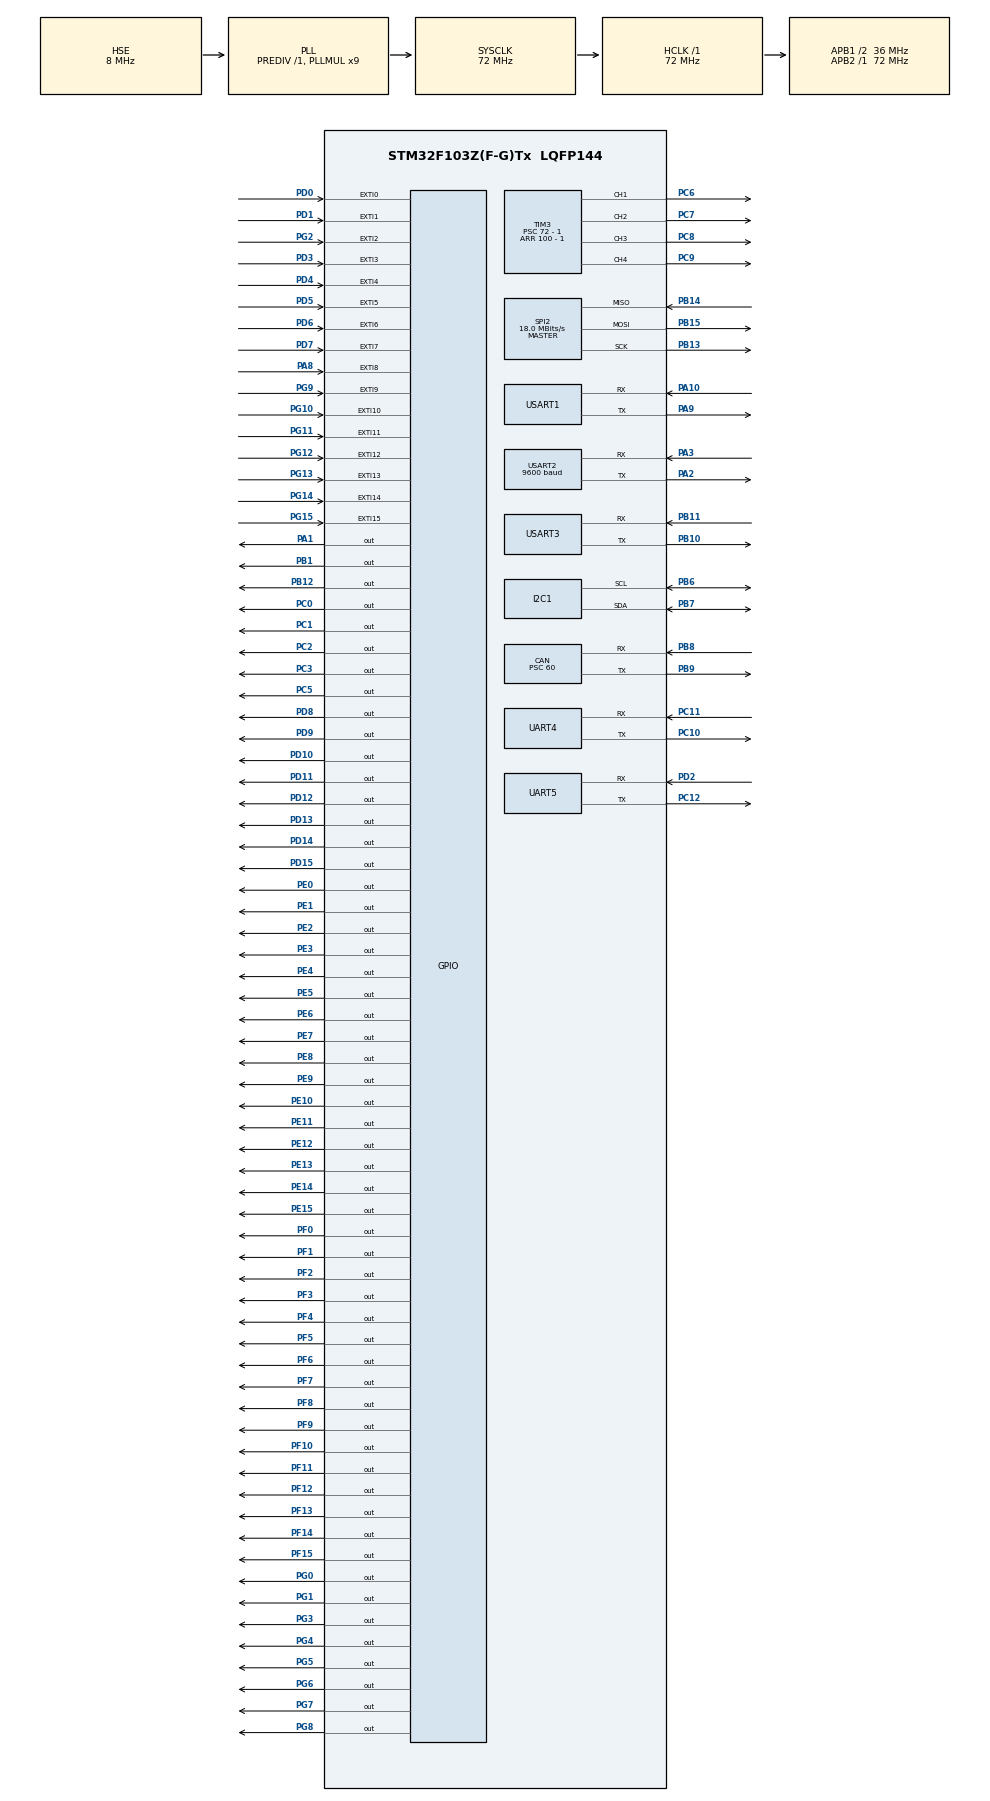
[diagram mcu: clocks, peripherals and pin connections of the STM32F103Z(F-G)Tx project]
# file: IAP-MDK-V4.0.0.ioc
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CAN.BS1=CAN_BS1_3TQ
CAN.BS2=CAN_BS2_2TQ
CAN.CalculateTimeBit=10000
CAN.CalculateTimeQuantum=1666.6666666666667
CAN.Prescaler=60
I2C1.AddressingMode=I2C_ADDRESSINGMODE_7BIT
I2C1.OwnAddress=0x0A
Mcu.Family=STM32F1
Mcu.Name=STM32F103Z(F-G)Tx
Mcu.Package=LQFP144
NVIC.EXTI0_IRQn=true\:0\:1\:true\:false\:true\:true
NVIC.EXTI15_10_IRQn=true\:0\:1\:false\:false\:true\:true
NVIC.EXTI1_IRQn=true\:0\:1\:true\:false\:true\:true
NVIC.EXTI2_IRQn=true\:0\:1\:false\:false\:true\:true
NVIC.EXTI3_IRQn=true\:0\:1\:false\:false\:true\:true
NVIC.EXTI4_IRQn=true\:0\:1\:false\:false\:true\:true
NVIC.EXTI9_5_IRQn=true\:0\:1\:false\:false\:true\:true
NVIC.I2C1_EV_IRQn=true\:0\:0\:false\:false\:true\:true
NVIC.PriorityGroup=NVIC_PRIORITYGROUP_2
NVIC.TIM1_BRK_TIM9_IRQn=true\:2\:0\:true\:false\:true\:true
NVIC.TIM1_TRG_COM_TIM11_IRQn=true\:2\:0\:true\:false\:true\:true
NVIC.TIM1_UP_TIM10_IRQn=true\:2\:0\:true\:false\:true\:true
NVIC.TIM5_IRQn=true\:2\:0\:true\:false\:true\:true
NVIC.TIM6_IRQn=true\:2\:0\:true\:false\:true\:true
NVIC.TIM7_IRQn=true\:2\:0\:true\:false\:true\:true
NVIC.TIM8_BRK_TIM12_IRQn=true\:2\:0\:true\:false\:true\:true
NVIC.TIM8_TRG_COM_TIM14_IRQn=true\:2\:0\:true\:false\:true\:true
NVIC.TIM8_UP_TIM13_IRQn=true\:2\:0\:true\:false\:true\:true
NVIC.UART4_IRQn=true\:1\:2\:true\:false\:true\:true
NVIC.UART5_IRQn=true\:1\:2\:true\:false\:true\:true
NVIC.USART1_IRQn=true\:1\:1\:true\:false\:true\:true
NVIC.USART2_IRQn=true\:1\:1\:true\:false\:true\:true
NVIC.USART3_IRQn=true\:1\:0\:true\:false\:true\:true
NVIC.USB_HP_CAN1_TX_IRQn=true\:0\:0\:false\:false\:true\:true
NVIC.USB_LP_CAN1_RX0_IRQn=true\:0\:0\:false\:false\:true\:false
OSC_IN.Mode=HSE-External-Oscillator
OSC_IN.Signal=RCC_OSC_IN
OSC_OUT.Mode=HSE-External-Oscillator
OSC_OUT.Signal=RCC_OSC_OUT
PA1.Signal=GPIO_Output
PA10.Mode=Asynchronous
PA10.Signal=USART1_RX
PA13.Mode=JTAG_5_pins
PA13.Signal=SYS_JTMS-SWDIO
PA14.Mode=JTAG_5_pins
PA14.Signal=SYS_JTCK-SWCLK
PA15.Mode=JTAG_5_pins
PA15.Signal=SYS_JTDI
PA2.Mode=Asynchronous
PA2.Signal=USART2_TX
PA3.Mode=Asynchronous
PA3.Signal=USART2_RX
PA8.GPIO_ModeDefaultEXTI=GPIO_MODE_IT_RISING_FALLING
PA8.Signal=GPXTI8
PA9.Mode=Asynchronous
PA9.Signal=USART1_TX
PB1.Signal=GPIO_Output
PB10.Mode=Asynchronous
PB10.Signal=USART3_TX
PB11.Mode=Asynchronous
PB11.Signal=USART3_RX
PB12.Signal=GPIO_Output
PB13.Mode=Full_Duplex_Master
PB13.Signal=SPI2_SCK
PB14.Mode=Full_Duplex_Master
PB14.Signal=SPI2_MISO
PB15.Mode=Full_Duplex_Master
PB15.Signal=SPI2_MOSI
PB3.Mode=JTAG_5_pins
PB3.Signal=SYS_JTDO-TRACESWO
PB4.Mode=JTAG_5_pins
PB4.Signal=SYS_NJTRST
PB6.Mode=I2C
PB6.Signal=I2C1_SCL
PB7.Mode=I2C
PB7.Signal=I2C1_SDA
PB8.Mode=Master
PB8.Signal=CAN_RX
PB9.Mode=Master
PB9.Signal=CAN_TX
PC0.Signal=GPIO_Output
PC1.Signal=GPIO_Output
PC10.Mode=Asynchronous
PC10.Signal=UART4_TX
PC11.Mode=Asynchronous
PC11.Signal=UART4_RX
PC12.Mode=Asynchronous
PC12.Signal=UART5_TX
PC14-OSC32_IN.Mode=LSE-External-Oscillator
PC14-OSC32_IN.Signal=RCC_OSC32_IN
PC15-OSC32_OUT.Mode=LSE-External-Oscillator
PC15-OSC32_OUT.Signal=RCC_OSC32_OUT
PC2.Signal=GPIO_Output
PC3.Signal=GPIO_Output
PC5.Signal=GPIO_Output
PC6.Signal=S_TIM3_CH1
PC7.Signal=S_TIM3_CH2
PC8.Signal=S_TIM3_CH3
PC9.Signal=S_TIM3_CH4
PD0.GPIO_ModeDefaultEXTI=GPIO_MODE_IT_RISING_FALLING
PD0.Signal=GPXTI0
PD1.GPIO_ModeDefaultEXTI=GPIO_MODE_IT_RISING_FALLING
PD1.Signal=GPXTI1
PD10.Signal=GPIO_Output
PD11.Signal=GPIO_Output
PD12.Signal=GPIO_Output
PD13.Signal=GPIO_Output
PD14.Signal=GPIO_Output
PD15.Signal=GPIO_Output
PD2.Mode=Asynchronous
PD2.Signal=UART5_RX
PD3.GPIO_ModeDefaultEXTI=GPIO_MODE_IT_RISING_FALLING
PD3.Signal=GPXTI3
PD4.GPIO_ModeDefaultEXTI=GPIO_MODE_IT_RISING_FALLING
PD4.Signal=GPXTI4
PD5.GPIO_ModeDefaultEXTI=GPIO_MODE_IT_RISING_FALLING
PD5.Signal=GPXTI5
PD6.GPIO_ModeDefaultEXTI=GPIO_MODE_IT_RISING_FALLING
PD6.Signal=GPXTI6
PD7.GPIO_ModeDefaultEXTI=GPIO_MODE_IT_RISING_FALLING
PD7.Signal=GPXTI7
PD8.Signal=GPIO_Output
PD9.Signal=GPIO_Output
PE0.Signal=GPIO_Output
PE1.Signal=GPIO_Output
PE10.Signal=GPIO_Output
PE11.Signal=GPIO_Output
PE12.Signal=GPIO_Output
PE13.Signal=GPIO_Output
PE14.Signal=GPIO_Output
PE15.Signal=GPIO_Output
PE2.Signal=GPIO_Output
PE3.Signal=GPIO_Output
PE4.Signal=GPIO_Output
PE5.Signal=GPIO_Output
PE6.Signal=GPIO_Output
PE7.Signal=GPIO_Output
PE8.Signal=GPIO_Output
PE9.Signal=GPIO_Output
PF0.Signal=GPIO_Output
PF1.Signal=GPIO_Output
PF10.Signal=GPIO_Output
PF11.Signal=GPIO_Output
PF12.Signal=GPIO_Output
PF13.Signal=GPIO_Output
PF14.Signal=GPIO_Output
PF15.Signal=GPIO_Output
PF2.Signal=GPIO_Output
PF3.Signal=GPIO_Output
PF4.Signal=GPIO_Output
PF5.Signal=GPIO_Output
PF6.Signal=GPIO_Output
PF7.Signal=GPIO_Output
PF8.Signal=GPIO_Output
PF9.Signal=GPIO_Output
PG0.Signal=GPIO_Output
PG1.Signal=GPIO_Output
PG10.GPIO_ModeDefaultEXTI=GPIO_MODE_IT_RISING_FALLING
PG10.Signal=GPXTI10
PG11.GPIO_ModeDefaultEXTI=GPIO_MODE_IT_RISING_FALLING
PG11.Signal=GPXTI11
PG12.GPIO_ModeDefaultEXTI=GPIO_MODE_IT_RISING_FALLING
PG12.Signal=GPXTI12
PG13.GPIO_ModeDefaultEXTI=GPIO_MODE_IT_RISING_FALLING
PG13.Signal=GPXTI13
PG14.GPIO_ModeDefaultEXTI=GPIO_MODE_IT_RISING_FALLING
PG14.Signal=GPXTI14
PG15.GPIO_ModeDefaultEXTI=GPIO_MODE_IT_RISING_FALLING
PG15.Signal=GPXTI15
PG2.GPIO_ModeDefaultEXTI=GPIO_MODE_IT_RISING_FALLING
PG2.Signal=GPXTI2
PG3.Signal=GPIO_Output
PG4.Signal=GPIO_Output
PG5.Signal=GPIO_Output
PG6.Signal=GPIO_Output
PG7.Signal=GPIO_Output
PG8.Signal=GPIO_Output
PG9.GPIO_ModeDefaultEXTI=GPIO_MODE_IT_RISING_FALLING
PG9.Signal=GPXTI9
ProjectManager.HeapSize=0x4000
ProjectManager.StackSize=0x5000
ProjectManager.TargetToolchain=MDK-ARM V5
RCC.AHBFreq_Value=72000000
RCC.APB1CLKDivider=RCC_HCLK_DIV2
RCC.APB1Freq_Value=36000000
RCC.APB1TimFreq_Value=72000000
RCC.APB2Freq_Value=72000000
RCC.APB2TimFreq_Value=72000000
RCC.HCLKFreq_Value=72000000
RCC.PLLMUL=RCC_PLL_MUL9
RCC.PLLSourceVirtual=RCC_PLLSOURCE_HSE
RCC.SYSCLKFreq_VALUE=72000000
RCC.SYSCLKSource=RCC_SYSCLKSOURCE_PLLCLK
RCC.USBFreq_Value=48000000
RCC.USBPrescaler=RCC_USBCLKSOURCE_PLL_DIV1_5
SH.S_TIM3_CH1.0=TIM3_CH1,PWM Generation1 CH1
SH.S_TIM3_CH2.0=TIM3_CH2,PWM Generation2 CH2
SH.S_TIM3_CH3.0=TIM3_CH3,PWM Generation3 CH3
SH.S_TIM3_CH4.0=TIM3_CH4,PWM Generation4 CH4
SPI2.BaudRatePrescaler=SPI_BAUDRATEPRESCALER_2
SPI2.CRCCalculation=SPI_CRCCALCULATION_ENABLE
SPI2.CalculateBaudRate=18.0 MBits/s
SPI2.Direction=SPI_DIRECTION_2LINES
SPI2.Mode=SPI_MODE_MASTER
SPI2.VirtualType=VM_MASTER
TIM10.Period=4 - 1
TIM10.Prescaler=72 - 1
TIM11.Period=4 - 1
TIM11.Prescaler=72 - 1
TIM12.Period=4 - 1
TIM12.Prescaler=72 - 1
TIM13.Period=4 - 1
TIM13.Prescaler=72 - 1
TIM14.Period=4 - 1
TIM14.Prescaler=72 - 1
TIM3.Channel-PWM\ Generation1\ CH1=TIM_CHANNEL_1
TIM3.Channel-PWM\ Generation2\ CH2=TIM_CHANNEL_2
TIM3.Channel-PWM\ Generation3\ CH3=TIM_CHANNEL_3
TIM3.Channel-PWM\ Generation4\ CH4=TIM_CHANNEL_4
TIM3.Period=100 - 1
TIM3.Prescaler=72 - 1
TIM5.Period=4 - 1
TIM5.Prescaler=72 - 1
TIM6.Period=4 - 1
TIM6.Prescaler=72 - 1
TIM7.Period=4 - 1
TIM7.Prescaler=72 - 1
TIM8.Period=4 - 1
TIM8.Prescaler=72 - 1
TIM9.Period=4 - 1
TIM9.Prescaler=72 - 1
UART4.VirtualMode=Asynchronous
UART5.VirtualMode=Asynchronous
USART1.VirtualMode=VM_ASYNC
USART2.BaudRate=9600
USART2.VirtualMode=VM_ASYNC
USART3.VirtualMode=VM_ASYNC
VP_TIM10_VS_ClockSourceINT.Mode=Enable_Timer
VP_TIM11_VS_ClockSourceINT.Mode=Enable_Timer
VP_TIM12_VS_ClockSourceINT.Mode=Internal
VP_TIM13_VS_ClockSourceINT.Mode=Enable_Timer
VP_TIM14_VS_ClockSourceINT.Mode=Enable_Timer
VP_TIM5_VS_ClockSourceINT.Mode=Internal
VP_TIM6_VS_ClockSourceINT.Mode=Enable_Timer
VP_TIM7_VS_ClockSourceINT.Mode=Enable_Timer
VP_TIM8_VS_ClockSourceINT.Mode=Internal
VP_TIM9_VS_ClockSourceINT.Mode=Internal
board=custom

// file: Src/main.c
/* USER CODE BEGIN Header */
/**
  ******************************************************************************
  * @file           : main.c
  * @brief          : Main program body
  ******************************************************************************
  * This notice applies to any and all portions of this file
  * that are not between comment pairs USER CODE BEGIN and
  * USER CODE END. Other portions of this file, whether
  * inserted by the user or by software development tools
  * are owned by their respective copyright owners.
  *
  * Copyright (c) 2019 STMicroelectronics International N.V.
  * All rights reserved.
  *
  * Redistribution and use in source and binary forms, with or without
  * modification, are permitted, provided that the following conditions are met:
  *
  * 1. Redistribution of source code must retain the above copyright notice,
  *    this list of conditions and the following disclaimer.
  * 2. Redistributions in binary form must reproduce the above copyright notice,
  *    this list of conditions and the following disclaimer in the documentation
  *    and/or other materials provided with the distribution.
  * 3. Neither the name of STMicroelectronics nor the names of other
  *    contributors to this software may be used to endorse or promote products
  *    derived from this software without specific written permission.
  * 4. This software, including modifications and/or derivative works of this
  *    software, must execute solely and exclusively on microcontroller or
  *    microprocessor devices manufactured by or for STMicroelectronics.
  * 5. Redistribution and use of this software other than as permitted under
  *    this license is void and will automatically terminate your rights under
  *    this license.
  *
  * THIS SOFTWARE IS PROVIDED BY STMICROELECTRONICS AND CONTRIBUTORS "AS IS"
  * AND ANY EXPRESS, IMPLIED OR STATUTORY WARRANTIES, INCLUDING, BUT NOT
  * LIMITED TO, THE IMPLIED WARRANTIES OF MERCHANTABILITY, FITNESS FOR A
  * PARTICULAR PURPOSE AND NON-INFRINGEMENT OF THIRD PARTY INTELLECTUAL PROPERTY
  * RIGHTS ARE DISCLAIMED TO THE FULLEST EXTENT PERMITTED BY LAW. IN NO EVENT
  * SHALL STMICROELECTRONICS OR CONTRIBUTORS BE LIABLE FOR ANY DIRECT, INDIRECT,
  * INCIDENTAL, SPECIAL, EXEMPLARY, OR CONSEQUENTIAL DAMAGES (INCLUDING, BUT NOT
  * LIMITED TO, PROCUREMENT OF SUBSTITUTE GOODS OR SERVICES; LOSS OF USE, DATA,
  * OR PROFITS; OR BUSINESS INTERRUPTION) HOWEVER CAUSED AND ON ANY THEORY OF
  * LIABILITY, WHETHER IN CONTRACT, STRICT LIABILITY, OR TORT (INCLUDING
  * NEGLIGENCE OR OTHERWISE) ARISING IN ANY WAY OUT OF THE USE OF THIS SOFTWARE,
  * EVEN IF ADVISED OF THE POSSIBILITY OF SUCH DAMAGE.
  *
  ******************************************************************************
  */
/* USER CODE END Header */

#include "main.h"

/* USER CODE BEGIN Includes */
#include "mb_type.h"
#include "mb_user.h"

#include "plc_user.h"
#include "plc_eep.h"

/* USER CODE END Includes */

CAN_HandleTypeDef hcan;

I2C_HandleTypeDef hi2c1;

SPI_HandleTypeDef hspi2;

TIM_HandleTypeDef htim3;
TIM_HandleTypeDef htim5;
TIM_HandleTypeDef htim6;
TIM_HandleTypeDef htim7;
TIM_HandleTypeDef htim8;
TIM_HandleTypeDef htim9;
TIM_HandleTypeDef htim10;
TIM_HandleTypeDef htim11;
TIM_HandleTypeDef htim12;
TIM_HandleTypeDef htim13;
TIM_HandleTypeDef htim14;

UART_HandleTypeDef huart4;
UART_HandleTypeDef huart5;
UART_HandleTypeDef huart1;
UART_HandleTypeDef huart2;
UART_HandleTypeDef huart3;

void SystemClock_Config(void);
static void MX_GPIO_Init(void);
static void MX_USART1_UART_Init(void);
static void MX_USART2_UART_Init(void);
static void MX_USART3_UART_Init(void);
static void MX_UART4_Init(void);
static void MX_UART5_Init(void);
static void MX_I2C1_Init(void);
static void MX_SPI2_Init(void);
static void MX_TIM3_Init(void);
static void MX_TIM11_Init(void);
static void MX_TIM7_Init(void);
static void MX_TIM8_Init(void);
static void MX_TIM9_Init(void);
static void MX_TIM10_Init(void);
static void MX_TIM12_Init(void);
static void MX_TIM13_Init(void);
static void MX_TIM14_Init(void);
static void MX_TIM6_Init(void);
static void MX_TIM5_Init(void);
static void MX_CAN_Init(void);

int main(void)
{
  /* USER CODE BEGIN 1 */
	uint8_t scan_enable;
	//uint8_t ReadValue;

  /* USER CODE END 1 */

  /* MCU Configuration--------------------------------------------------------*/

  /* Reset of all peripherals, Initializes the Flash interface and the Systick. */
  HAL_Init();

  /* Configure the system clock */
  SystemClock_Config();

  /* Initialize all configured peripherals */
  MX_GPIO_Init();
  MX_USART1_UART_Init();
  MX_USART2_UART_Init();
  MX_USART3_UART_Init();
  MX_UART4_Init();
  MX_UART5_Init();
  MX_I2C1_Init();
  MX_SPI2_Init();
  MX_TIM3_Init();
  MX_TIM11_Init();
  MX_TIM7_Init();
  MX_TIM8_Init();
  MX_TIM9_Init();
  MX_TIM10_Init();
  MX_TIM12_Init();
  MX_TIM13_Init();
  MX_TIM14_Init();
  MX_TIM6_Init();
  MX_TIM5_Init();
  MX_CAN_Init();
  /* USER CODE BEGIN 2 */
	// 时钟节拍
	HAL_SetTickFreq(HAL_TICK_FREQ_1KHZ);

	// 端口初始化
	plc_user_init();

	//modbus 端口初始化
	mb_user_init();

  /* USER CODE END 2 */

  /* Infinite loop */
  /* USER CODE BEGIN WHILE */
  while (1)
  {
	  // plc扫描
		scan_enable = plc_user_scan(scan_enable);

		// modbus扫描
		if(scan_enable == FALSE){
			scan_enable = mb_user_poll();
		}

    /* USER CODE END WHILE */

  }
}

void SystemClock_Config(void)
{
  RCC_OscInitTypeDef RCC_OscInitStruct = {0};
  RCC_ClkInitTypeDef RCC_ClkInitStruct = {0};

  /**Initializes the CPU, AHB and APB busses clocks
  */
  RCC_OscInitStruct.OscillatorType = RCC_OSCILLATORTYPE_HSE;
  RCC_OscInitStruct.HSEState = RCC_HSE_ON;
  RCC_OscInitStruct.HSEPredivValue = RCC_HSE_PREDIV_DIV1;
  RCC_OscInitStruct.HSIState = RCC_HSI_ON;
  RCC_OscInitStruct.PLL.PLLState = RCC_PLL_ON;
  RCC_OscInitStruct.PLL.PLLSource = RCC_PLLSOURCE_HSE;
  RCC_OscInitStruct.PLL.PLLMUL = RCC_PLL_MUL9;
  if (HAL_RCC_OscConfig(&RCC_OscInitStruct) != HAL_OK)
  {
    Error_Handler();
  }
  /**Initializes the CPU, AHB and APB busses clocks
  */
  RCC_ClkInitStruct.ClockType = RCC_CLOCKTYPE_HCLK|RCC_CLOCKTYPE_SYSCLK
                              |RCC_CLOCKTYPE_PCLK1|RCC_CLOCKTYPE_PCLK2;
  RCC_ClkInitStruct.SYSCLKSource = RCC_SYSCLKSOURCE_PLLCLK;
  RCC_ClkInitStruct.AHBCLKDivider = RCC_SYSCLK_DIV1;
  RCC_ClkInitStruct.APB1CLKDivider = RCC_HCLK_DIV2;
  RCC_ClkInitStruct.APB2CLKDivider = RCC_HCLK_DIV1;

  if (HAL_RCC_ClockConfig(&RCC_ClkInitStruct, FLASH_LATENCY_2) != HAL_OK)
  {
    Error_Handler();
  }
}

static void MX_CAN_Init(void)
{

  hcan.Instance = CAN1;
  hcan.Init.Prescaler = 60;
  hcan.Init.Mode = CAN_MODE_NORMAL;
  hcan.Init.SyncJumpWidth = CAN_SJW_1TQ;
  hcan.Init.TimeSeg1 = CAN_BS1_3TQ;
  hcan.Init.TimeSeg2 = CAN_BS2_2TQ;
  hcan.Init.TimeTriggeredMode = DISABLE;
  hcan.Init.AutoBusOff = DISABLE;
  hcan.Init.AutoWakeUp = DISABLE;
  hcan.Init.AutoRetransmission = DISABLE;
  hcan.Init.ReceiveFifoLocked = DISABLE;
  hcan.Init.TransmitFifoPriority = DISABLE;
  if (HAL_CAN_Init(&hcan) != HAL_OK)
  {
    Error_Handler();
  }

}

static void MX_I2C1_Init(void)
{

  hi2c1.Instance = I2C1;
  hi2c1.Init.ClockSpeed = 100000;
  hi2c1.Init.DutyCycle = I2C_DUTYCYCLE_2;
  hi2c1.Init.OwnAddress1 = 20;
  hi2c1.Init.AddressingMode = I2C_ADDRESSINGMODE_7BIT;
  hi2c1.Init.DualAddressMode = I2C_DUALADDRESS_DISABLE;
  hi2c1.Init.OwnAddress2 = 0;
  hi2c1.Init.GeneralCallMode = I2C_GENERALCALL_DISABLE;
  hi2c1.Init.NoStretchMode = I2C_NOSTRETCH_DISABLE;
  if (HAL_I2C_Init(&hi2c1) != HAL_OK)
  {
    Error_Handler();
  }

}

static void MX_SPI2_Init(void)
{

  /* SPI2 parameter configuration*/
  hspi2.Instance = SPI2;
  hspi2.Init.Mode = SPI_MODE_MASTER;
  hspi2.Init.Direction = SPI_DIRECTION_2LINES;
  hspi2.Init.DataSize = SPI_DATASIZE_8BIT;
  hspi2.Init.CLKPolarity = SPI_POLARITY_LOW;
  hspi2.Init.CLKPhase = SPI_PHASE_1EDGE;
  hspi2.Init.NSS = SPI_NSS_SOFT;
  hspi2.Init.BaudRatePrescaler = SPI_BAUDRATEPRESCALER_2;
  hspi2.Init.FirstBit = SPI_FIRSTBIT_MSB;
  hspi2.Init.TIMode = SPI_TIMODE_DISABLE;
  hspi2.Init.CRCCalculation = SPI_CRCCALCULATION_ENABLE;
  hspi2.Init.CRCPolynomial = 10;
  if (HAL_SPI_Init(&hspi2) != HAL_OK)
  {
    Error_Handler();
  }

}

static void MX_TIM3_Init(void)
{

  TIM_MasterConfigTypeDef sMasterConfig = {0};
  TIM_OC_InitTypeDef sConfigOC = {0};

  htim3.Instance = TIM3;
  htim3.Init.Prescaler = 72 - 1;
  htim3.Init.CounterMode = TIM_COUNTERMODE_UP;
  htim3.Init.Period = 100 - 1;
  htim3.Init.ClockDivision = TIM_CLOCKDIVISION_DIV1;
  htim3.Init.AutoReloadPreload = TIM_AUTORELOAD_PRELOAD_DISABLE;
  if (HAL_TIM_PWM_Init(&htim3) != HAL_OK)
  {
    Error_Handler();
  }
  sMasterConfig.MasterOutputTrigger = TIM_TRGO_RESET;
  sMasterConfig.MasterSlaveMode = TIM_MASTERSLAVEMODE_DISABLE;
  if (HAL_TIMEx_MasterConfigSynchronization(&htim3, &sMasterConfig) != HAL_OK)
  {
    Error_Handler();
  }
  sConfigOC.OCMode = TIM_OCMODE_PWM1;
  sConfigOC.Pulse = 0;
  sConfigOC.OCPolarity = TIM_OCPOLARITY_HIGH;
  sConfigOC.OCFastMode = TIM_OCFAST_DISABLE;
  if (HAL_TIM_PWM_ConfigChannel(&htim3, &sConfigOC, TIM_CHANNEL_1) != HAL_OK)
  {
    Error_Handler();
  }
  if (HAL_TIM_PWM_ConfigChannel(&htim3, &sConfigOC, TIM_CHANNEL_2) != HAL_OK)
  {
    Error_Handler();
  }
  if (HAL_TIM_PWM_ConfigChannel(&htim3, &sConfigOC, TIM_CHANNEL_3) != HAL_OK)
  {
    Error_Handler();
  }
  if (HAL_TIM_PWM_ConfigChannel(&htim3, &sConfigOC, TIM_CHANNEL_4) != HAL_OK)
  {
    Error_Handler();
  }
  HAL_TIM_MspPostInit(&htim3);

}

static void MX_TIM5_Init(void)
{

  TIM_ClockConfigTypeDef sClockSourceConfig = {0};
  TIM_MasterConfigTypeDef sMasterConfig = {0};

  htim5.Instance = TIM5;
  htim5.Init.Prescaler = 72 - 1;
  htim5.Init.CounterMode = TIM_COUNTERMODE_UP;
  htim5.Init.Period = 4 - 1;
  htim5.Init.ClockDivision = TIM_CLOCKDIVISION_DIV1;
  htim5.Init.AutoReloadPreload = TIM_AUTORELOAD_PRELOAD_DISABLE;
  if (HAL_TIM_Base_Init(&htim5) != HAL_OK)
  {
    Error_Handler();
  }
  sClockSourceConfig.ClockSource = TIM_CLOCKSOURCE_INTERNAL;
  if (HAL_TIM_ConfigClockSource(&htim5, &sClockSourceConfig) != HAL_OK)
  {
    Error_Handler();
  }
  sMasterConfig.MasterOutputTrigger = TIM_TRGO_RESET;
  sMasterConfig.MasterSlaveMode = TIM_MASTERSLAVEMODE_DISABLE;
  if (HAL_TIMEx_MasterConfigSynchronization(&htim5, &sMasterConfig) != HAL_OK)
  {
    Error_Handler();
  }

}

static void MX_TIM6_Init(void)
{

  TIM_MasterConfigTypeDef sMasterConfig = {0};

  htim6.Instance = TIM6;
  htim6.Init.Prescaler = 72 - 1;
  htim6.Init.CounterMode = TIM_COUNTERMODE_UP;
  htim6.Init.Period = 4 - 1;
  htim6.Init.AutoReloadPreload = TIM_AUTORELOAD_PRELOAD_DISABLE;
  if (HAL_TIM_Base_Init(&htim6) != HAL_OK)
  {
    Error_Handler();
  }
  sMasterConfig.MasterOutputTrigger = TIM_TRGO_RESET;
  sMasterConfig.MasterSlaveMode = TIM_MASTERSLAVEMODE_DISABLE;
  if (HAL_TIMEx_MasterConfigSynchronization(&htim6, &sMasterConfig) != HAL_OK)
  {
    Error_Handler();
  }

}

static void MX_TIM7_Init(void)
{

  TIM_MasterConfigTypeDef sMasterConfig = {0};

  htim7.Instance = TIM7;
  htim7.Init.Prescaler = 72 - 1;
  htim7.Init.CounterMode = TIM_COUNTERMODE_UP;
  htim7.Init.Period = 4 - 1;
  htim7.Init.AutoReloadPreload = TIM_AUTORELOAD_PRELOAD_DISABLE;
  if (HAL_TIM_Base_Init(&htim7) != HAL_OK)
  {
    Error_Handler();
  }
  sMasterConfig.MasterOutputTrigger = TIM_TRGO_RESET;
  sMasterConfig.MasterSlaveMode = TIM_MASTERSLAVEMODE_DISABLE;
  if (HAL_TIMEx_MasterConfigSynchronization(&htim7, &sMasterConfig) != HAL_OK)
  {
    Error_Handler();
  }

}

static void MX_TIM8_Init(void)
{

  TIM_ClockConfigTypeDef sClockSourceConfig = {0};
  TIM_MasterConfigTypeDef sMasterConfig = {0};

  htim8.Instance = TIM8;
  htim8.Init.Prescaler = 72 - 1;
  htim8.Init.CounterMode = TIM_COUNTERMODE_UP;
  htim8.Init.Period = 4 - 1;
  htim8.Init.ClockDivision = TIM_CLOCKDIVISION_DIV1;
  htim8.Init.RepetitionCounter = 0;
  htim8.Init.AutoReloadPreload = TIM_AUTORELOAD_PRELOAD_DISABLE;
  if (HAL_TIM_Base_Init(&htim8) != HAL_OK)
  {
    Error_Handler();
  }
  sClockSourceConfig.ClockSource = TIM_CLOCKSOURCE_INTERNAL;
  if (HAL_TIM_ConfigClockSource(&htim8, &sClockSourceConfig) != HAL_OK)
  {
    Error_Handler();
  }
  sMasterConfig.MasterOutputTrigger = TIM_TRGO_RESET;
  sMasterConfig.MasterSlaveMode = TIM_MASTERSLAVEMODE_DISABLE;
  if (HAL_TIMEx_MasterConfigSynchronization(&htim8, &sMasterConfig) != HAL_OK)
  {
    Error_Handler();
  }

}

static void MX_TIM9_Init(void)
{

  TIM_ClockConfigTypeDef sClockSourceConfig = {0};

  htim9.Instance = TIM9;
  htim9.Init.Prescaler = 72 - 1;
  htim9.Init.CounterMode = TIM_COUNTERMODE_UP;
  htim9.Init.Period = 4 - 1;
  htim9.Init.ClockDivision = TIM_CLOCKDIVISION_DIV1;
  htim9.Init.AutoReloadPreload = TIM_AUTORELOAD_PRELOAD_DISABLE;
  if (HAL_TIM_Base_Init(&htim9) != HAL_OK)
  {
    Error_Handler();
  }
  sClockSourceConfig.ClockSource = TIM_CLOCKSOURCE_INTERNAL;
  if (HAL_TIM_ConfigClockSource(&htim9, &sClockSourceConfig) != HAL_OK)
  {
    Error_Handler();
  }

}

static void MX_TIM10_Init(void)
{

  htim10.Instance = TIM10;
  htim10.Init.Prescaler = 72 - 1;
  htim10.Init.CounterMode = TIM_COUNTERMODE_UP;
  htim10.Init.Period = 4 - 1;
  htim10.Init.ClockDivision = TIM_CLOCKDIVISION_DIV1;
  htim10.Init.AutoReloadPreload = TIM_AUTORELOAD_PRELOAD_DISABLE;
  if (HAL_TIM_Base_Init(&htim10) != HAL_OK)
  {
    Error_Handler();
  }

}

static void MX_TIM11_Init(void)
{

  htim11.Instance = TIM11;
  htim11.Init.Prescaler = 72 - 1;
  htim11.Init.CounterMode = TIM_COUNTERMODE_UP;
  htim11.Init.Period = 4 - 1;
  htim11.Init.ClockDivision = TIM_CLOCKDIVISION_DIV1;
  htim11.Init.AutoReloadPreload = TIM_AUTORELOAD_PRELOAD_DISABLE;
  if (HAL_TIM_Base_Init(&htim11) != HAL_OK)
  {
    Error_Handler();
  }

}

static void MX_TIM12_Init(void)
{

  TIM_ClockConfigTypeDef sClockSourceConfig = {0};

  htim12.Instance = TIM12;
  htim12.Init.Prescaler = 72 - 1;
  htim12.Init.CounterMode = TIM_COUNTERMODE_UP;
  htim12.Init.Period = 4 - 1;
  htim12.Init.ClockDivision = TIM_CLOCKDIVISION_DIV1;
  htim12.Init.AutoReloadPreload = TIM_AUTORELOAD_PRELOAD_DISABLE;
  if (HAL_TIM_Base_Init(&htim12) != HAL_OK)
  {
    Error_Handler();
  }
  sClockSourceConfig.ClockSource = TIM_CLOCKSOURCE_INTERNAL;
  if (HAL_TIM_ConfigClockSource(&htim12, &sClockSourceConfig) != HAL_OK)
  {
    Error_Handler();
  }

}

static void MX_TIM13_Init(void)
{

  htim13.Instance = TIM13;
  htim13.Init.Prescaler = 72 - 1;
  htim13.Init.CounterMode = TIM_COUNTERMODE_UP;
  htim13.Init.Period = 4 - 1;
  htim13.Init.ClockDivision = TIM_CLOCKDIVISION_DIV1;
  htim13.Init.AutoReloadPreload = TIM_AUTORELOAD_PRELOAD_DISABLE;
  if (HAL_TIM_Base_Init(&htim13) != HAL_OK)
  {
    Error_Handler();
  }

}

static void MX_TIM14_Init(void)
{

  htim14.Instance = TIM14;
  htim14.Init.Prescaler = 72 - 1;
  htim14.Init.CounterMode = TIM_COUNTERMODE_UP;
  htim14.Init.Period = 4 - 1;
  htim14.Init.ClockDivision = TIM_CLOCKDIVISION_DIV1;
  htim14.Init.AutoReloadPreload = TIM_AUTORELOAD_PRELOAD_DISABLE;
  if (HAL_TIM_Base_Init(&htim14) != HAL_OK)
  {
    Error_Handler();
  }

}

static void MX_UART4_Init(void)
{

  huart4.Instance = UART4;
  huart4.Init.BaudRate = 115200;
  huart4.Init.WordLength = UART_WORDLENGTH_8B;
  huart4.Init.StopBits = UART_STOPBITS_1;
  huart4.Init.Parity = UART_PARITY_NONE;
  huart4.Init.Mode = UART_MODE_TX_RX;
  huart4.Init.HwFlowCtl = UART_HWCONTROL_NONE;
  huart4.Init.OverSampling = UART_OVERSAMPLING_16;
  if (HAL_UART_Init(&huart4) != HAL_OK)
  {
    Error_Handler();
  }

}

static void MX_UART5_Init(void)
{

  huart5.Instance = UART5;
  huart5.Init.BaudRate = 115200;
  huart5.Init.WordLength = UART_WORDLENGTH_8B;
  huart5.Init.StopBits = UART_STOPBITS_1;
  huart5.Init.Parity = UART_PARITY_NONE;
  huart5.Init.Mode = UART_MODE_TX_RX;
  huart5.Init.HwFlowCtl = UART_HWCONTROL_NONE;
  huart5.Init.OverSampling = UART_OVERSAMPLING_16;
  if (HAL_UART_Init(&huart5) != HAL_OK)
  {
    Error_Handler();
  }

}

static void MX_USART1_UART_Init(void)
{

  huart1.Instance = USART1;
  huart1.Init.BaudRate = 115200;
  huart1.Init.WordLength = UART_WORDLENGTH_8B;
  huart1.Init.StopBits = UART_STOPBITS_1;
  huart1.Init.Parity = UART_PARITY_NONE;
  huart1.Init.Mode = UART_MODE_TX_RX;
  huart1.Init.HwFlowCtl = UART_HWCONTROL_NONE;
  huart1.Init.OverSampling = UART_OVERSAMPLING_16;
  if (HAL_UART_Init(&huart1) != HAL_OK)
  {
    Error_Handler();
  }

}

static void MX_USART2_UART_Init(void)
{

  huart2.Instance = USART2;
  huart2.Init.BaudRate = 9600;
  huart2.Init.WordLength = UART_WORDLENGTH_8B;
  huart2.Init.StopBits = UART_STOPBITS_1;
  huart2.Init.Parity = UART_PARITY_NONE;
  huart2.Init.Mode = UART_MODE_TX_RX;
  huart2.Init.HwFlowCtl = UART_HWCONTROL_NONE;
  huart2.Init.OverSampling = UART_OVERSAMPLING_16;
  if (HAL_UART_Init(&huart2) != HAL_OK)
  {
    Error_Handler();
  }

}

static void MX_USART3_UART_Init(void)
{

  huart3.Instance = USART3;
  huart3.Init.BaudRate = 115200;
  huart3.Init.WordLength = UART_WORDLENGTH_8B;
  huart3.Init.StopBits = UART_STOPBITS_1;
  huart3.Init.Parity = UART_PARITY_NONE;
  huart3.Init.Mode = UART_MODE_TX_RX;
  huart3.Init.HwFlowCtl = UART_HWCONTROL_NONE;
  huart3.Init.OverSampling = UART_OVERSAMPLING_16;
  if (HAL_UART_Init(&huart3) != HAL_OK)
  {
    Error_Handler();
  }

}

static void MX_GPIO_Init(void)
{
  GPIO_InitTypeDef GPIO_InitStruct = {0};

  /* GPIO Ports Clock Enable */
  __HAL_RCC_GPIOE_CLK_ENABLE();
  __HAL_RCC_GPIOC_CLK_ENABLE();
  __HAL_RCC_GPIOF_CLK_ENABLE();
  __HAL_RCC_GPIOA_CLK_ENABLE();
  __HAL_RCC_GPIOB_CLK_ENABLE();
  __HAL_RCC_GPIOG_CLK_ENABLE();
  __HAL_RCC_GPIOD_CLK_ENABLE();

  /*Configure GPIO pin Output Level */
  HAL_GPIO_WritePin(GPIOE, GPIO_PIN_2|GPIO_PIN_3|GPIO_PIN_4|GPIO_PIN_5
                          |GPIO_PIN_6|GPIO_PIN_7|GPIO_PIN_8|GPIO_PIN_9
                          |GPIO_PIN_10|GPIO_PIN_11|GPIO_PIN_12|GPIO_PIN_13
                          |GPIO_PIN_14|GPIO_PIN_15|GPIO_PIN_0|GPIO_PIN_1, GPIO_PIN_RESET);

  /*Configure GPIO pin Output Level */
  HAL_GPIO_WritePin(GPIOF, GPIO_PIN_0|GPIO_PIN_1|GPIO_PIN_2|GPIO_PIN_3
                          |GPIO_PIN_4|GPIO_PIN_5|GPIO_PIN_6|GPIO_PIN_7
                          |GPIO_PIN_8|GPIO_PIN_9|GPIO_PIN_10|GPIO_PIN_11
                          |GPIO_PIN_12|GPIO_PIN_13|GPIO_PIN_14|GPIO_PIN_15, GPIO_PIN_RESET);

  /*Configure GPIO pin Output Level */
  HAL_GPIO_WritePin(GPIOC, GPIO_PIN_0|GPIO_PIN_1|GPIO_PIN_2|GPIO_PIN_3
                          |GPIO_PIN_5, GPIO_PIN_RESET);

  /*Configure GPIO pin Output Level */
  HAL_GPIO_WritePin(GPIOA, GPIO_PIN_1, GPIO_PIN_RESET);

  /*Configure GPIO pin Output Level */
  HAL_GPIO_WritePin(GPIOB, GPIO_PIN_1|GPIO_PIN_12, GPIO_PIN_RESET);

  /*Configure GPIO pin Output Level */
  HAL_GPIO_WritePin(GPIOG, GPIO_PIN_0|GPIO_PIN_1|GPIO_PIN_3|GPIO_PIN_4
                          |GPIO_PIN_5|GPIO_PIN_6|GPIO_PIN_7|GPIO_PIN_8, GPIO_PIN_RESET);

  /*Configure GPIO pin Output Level */
  HAL_GPIO_WritePin(GPIOD, GPIO_PIN_8|GPIO_PIN_9|GPIO_PIN_10|GPIO_PIN_11
                          |GPIO_PIN_12|GPIO_PIN_13|GPIO_PIN_14|GPIO_PIN_15, GPIO_PIN_RESET);

  /*Configure GPIO pins : PE2 PE3 PE4 PE5
                           PE6 PE7 PE8 PE9
                           PE10 PE11 PE12 PE13
                           PE14 PE15 PE0 PE1 */
  GPIO_InitStruct.Pin = GPIO_PIN_2|GPIO_PIN_3|GPIO_PIN_4|GPIO_PIN_5
                          |GPIO_PIN_6|GPIO_PIN_7|GPIO_PIN_8|GPIO_PIN_9
                          |GPIO_PIN_10|GPIO_PIN_11|GPIO_PIN_12|GPIO_PIN_13
                          |GPIO_PIN_14|GPIO_PIN_15|GPIO_PIN_0|GPIO_PIN_1;
  GPIO_InitStruct.Mode = GPIO_MODE_OUTPUT_PP;//推挽输出
  GPIO_InitStruct.Pull = GPIO_NOPULL;
  GPIO_InitStruct.Speed = GPIO_SPEED_FREQ_LOW;
  HAL_GPIO_Init(GPIOE, &GPIO_InitStruct);

  /*Configure GPIO pins : PF0 PF1 PF2 PF3
                           PF4 PF5 PF6 PF7
                           PF8 PF9 PF10 PF11
                           PF12 PF13 PF14 PF15 */
  GPIO_InitStruct.Pin = GPIO_PIN_0|GPIO_PIN_1|GPIO_PIN_2|GPIO_PIN_3
                          |GPIO_PIN_4|GPIO_PIN_5|GPIO_PIN_6|GPIO_PIN_7
                          |GPIO_PIN_8|GPIO_PIN_9|GPIO_PIN_10|GPIO_PIN_11
                          |GPIO_PIN_12|GPIO_PIN_13|GPIO_PIN_14|GPIO_PIN_15;
  GPIO_InitStruct.Mode = GPIO_MODE_OUTPUT_PP;
  GPIO_InitStruct.Pull = GPIO_NOPULL;
  GPIO_InitStruct.Speed = GPIO_SPEED_FREQ_LOW;
  HAL_GPIO_Init(GPIOF, &GPIO_InitStruct);

  /*Configure GPIO pins : PC0 PC1 PC2 PC3
                           PC5 */
  GPIO_InitStruct.Pin = GPIO_PIN_0|GPIO_PIN_1|GPIO_PIN_2|GPIO_PIN_3
                          |GPIO_PIN_5;
  GPIO_InitStruct.Mode = GPIO_MODE_OUTPUT_PP;
  GPIO_InitStruct.Pull = GPIO_NOPULL;
  GPIO_InitStruct.Speed = GPIO_SPEED_FREQ_LOW;
  HAL_GPIO_Init(GPIOC, &GPIO_InitStruct);

  /*Configure GPIO pin : PA1 */
  GPIO_InitStruct.Pin = GPIO_PIN_1;
  GPIO_InitStruct.Mode = GPIO_MODE_OUTPUT_PP;
  GPIO_InitStruct.Pull = GPIO_NOPULL;
  GPIO_InitStruct.Speed = GPIO_SPEED_FREQ_LOW;
  HAL_GPIO_Init(GPIOA, &GPIO_InitStruct);

  /*Configure GPIO pins : PB1 PB12 */
  GPIO_InitStruct.Pin = GPIO_PIN_1|GPIO_PIN_12;
  GPIO_InitStruct.Mode = GPIO_MODE_OUTPUT_PP;
  GPIO_InitStruct.Pull = GPIO_NOPULL;
  GPIO_InitStruct.Speed = GPIO_SPEED_FREQ_LOW;
  HAL_GPIO_Init(GPIOB, &GPIO_InitStruct);

  /*Configure GPIO pins : PG0 PG1 PG3 PG4
                           PG5 PG6 PG7 PG8 */
  GPIO_InitStruct.Pin = GPIO_PIN_0|GPIO_PIN_1|GPIO_PIN_3|GPIO_PIN_4
                          |GPIO_PIN_5|GPIO_PIN_6|GPIO_PIN_7|GPIO_PIN_8;
  GPIO_InitStruct.Mode = GPIO_MODE_OUTPUT_PP;
  GPIO_InitStruct.Pull = GPIO_NOPULL;
  GPIO_InitStruct.Speed = GPIO_SPEED_FREQ_LOW;
  HAL_GPIO_Init(GPIOG, &GPIO_InitStruct);

  /*Configure GPIO pins : PD8 PD9 PD10 PD11
                           PD12 PD13 PD14 PD15 */
  GPIO_InitStruct.Pin = GPIO_PIN_8|GPIO_PIN_9|GPIO_PIN_10|GPIO_PIN_11
                          |GPIO_PIN_12|GPIO_PIN_13|GPIO_PIN_14|GPIO_PIN_15;
  GPIO_InitStruct.Mode = GPIO_MODE_OUTPUT_PP;
  GPIO_InitStruct.Pull = GPIO_NOPULL;
  GPIO_InitStruct.Speed = GPIO_SPEED_FREQ_LOW;
  HAL_GPIO_Init(GPIOD, &GPIO_InitStruct);

  /*Configure GPIO pins : PG2 PG9 PG10 PG11
                           PG12 PG13 PG14 PG15 */
  GPIO_InitStruct.Pin = GPIO_PIN_2|GPIO_PIN_9|GPIO_PIN_10|GPIO_PIN_11
                          |GPIO_PIN_12|GPIO_PIN_13|GPIO_PIN_14|GPIO_PIN_15;
  GPIO_InitStruct.Mode = GPIO_MODE_IT_RISING_FALLING;
  GPIO_InitStruct.Pull = GPIO_NOPULL;
  HAL_GPIO_Init(GPIOG, &GPIO_InitStruct);

  /*Configure GPIO pin : PA8 */
  GPIO_InitStruct.Pin = GPIO_PIN_8;
  GPIO_InitStruct.Mode = GPIO_MODE_IT_RISING_FALLING;
  GPIO_InitStruct.Pull = GPIO_NOPULL;
  HAL_GPIO_Init(GPIOA, &GPIO_InitStruct);

  /*Configure GPIO pins : PD0 PD1 PD3 PD4
                           PD5 PD6 PD7 */
  GPIO_InitStruct.Pin = GPIO_PIN_0|GPIO_PIN_1|GPIO_PIN_3|GPIO_PIN_4
                          |GPIO_PIN_5|GPIO_PIN_6|GPIO_PIN_7;
  GPIO_InitStruct.Mode = GPIO_MODE_IT_RISING_FALLING;
  GPIO_InitStruct.Pull = GPIO_NOPULL;
  HAL_GPIO_Init(GPIOD, &GPIO_InitStruct);

  /* EXTI interrupt init*/
  HAL_NVIC_SetPriority(EXTI0_IRQn, 0, 1);
  HAL_NVIC_EnableIRQ(EXTI0_IRQn);

  HAL_NVIC_SetPriority(EXTI1_IRQn, 0, 1);
  HAL_NVIC_EnableIRQ(EXTI1_IRQn);

  HAL_NVIC_SetPriority(EXTI2_IRQn, 0, 1);
  HAL_NVIC_EnableIRQ(EXTI2_IRQn);

  HAL_NVIC_SetPriority(EXTI3_IRQn, 0, 1);
  HAL_NVIC_EnableIRQ(EXTI3_IRQn);

  HAL_NVIC_SetPriority(EXTI4_IRQn, 0, 1);
  HAL_NVIC_EnableIRQ(EXTI4_IRQn);

  HAL_NVIC_SetPriority(EXTI9_5_IRQn, 0, 1);
  HAL_NVIC_EnableIRQ(EXTI9_5_IRQn);

  HAL_NVIC_SetPriority(EXTI15_10_IRQn, 0, 1);
  HAL_NVIC_EnableIRQ(EXTI15_10_IRQn);

}

void Error_Handler(void)
{
}

/************************ (C) COPYRIGHT STMicroelectronics *****END OF FILE****/
